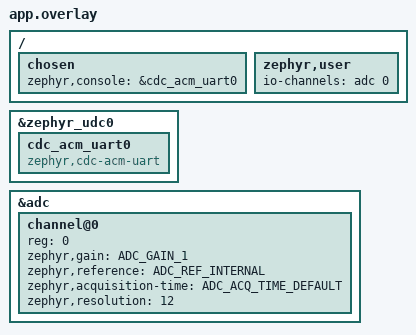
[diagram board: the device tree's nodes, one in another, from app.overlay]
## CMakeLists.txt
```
cmake_minimum_required(VERSION 3.20.0)
find_package(Zephyr REQUIRED HINTS $ENV{ZEPHYR_BASE})
project(temp-sensor)

target_sources(app PRIVATE src/main.c)
```

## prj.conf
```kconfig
CONFIG_SERIAL=y
CONFIG_CONSOLE=y
CONFIG_UART_CONSOLE=y
CONFIG_UART_LINE_CTRL=y

CONFIG_USB_DEVICE_STACK=y
CONFIG_USB_DEVICE_PRODUCT="Zephyr Temp Sensor"
CONFIG_USB_CDC_ACM=y

CONFIG_ADC=y
```

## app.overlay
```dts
#include <zephyr/dt-bindings/adc/adc.h>

/ {
	chosen {
		zephyr,console = &cdc_acm_uart0;
	};

	zephyr,user {
		io-channels = <&adc 0>;
	};
};

&zephyr_udc0 {
	cdc_acm_uart0: cdc_acm_uart0 {
		compatible = "zephyr,cdc-acm-uart";
	};
};

&adc {
	#address-cells = <1>;
	#size-cells = <0>;

	channel@0 {
		reg = <0>;
		zephyr,gain = "ADC_GAIN_1";
		zephyr,reference = "ADC_REF_INTERNAL";
		zephyr,acquisition-time = <ADC_ACQ_TIME_DEFAULT>;
		zephyr,resolution = <12>;
	};
};
```

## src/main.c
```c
#include <zephyr/kernel.h>
#include <zephyr/device.h>
#include <zephyr/drivers/uart.h>
#include <zephyr/drivers/adc.h>
#include <zephyr/usb/usb_device.h>

static const struct adc_dt_spec adc_chan =
	ADC_DT_SPEC_GET(DT_PATH(zephyr_user));

int main(void)
{
	const struct device *const console = DEVICE_DT_GET(DT_CHOSEN(zephyr_console));
	uint32_t dtr = 0;

	if (usb_enable(NULL)) {
		return 0;
	}

	while (!dtr) {
		uart_line_ctrl_get(console, UART_LINE_CTRL_DTR, &dtr);
		k_sleep(K_MSEC(100));
	}

	if (!adc_is_ready_dt(&adc_chan)) {
		printk("ADC not ready\n");
		return 0;
	}

	if (adc_channel_setup_dt(&adc_chan) < 0) {
		printk("ADC channel setup failed\n");
		return 0;
	}

	int16_t sample;
	struct adc_sequence seq = {
		.buffer = &sample,
		.buffer_size = sizeof(sample),
	};
	adc_sequence_init_dt(&adc_chan, &seq);

	printk("Temp sensor app started\n");

	const int N = 256;

	while (1) {
		int32_t raw_sum = 0;
		int good = 0;

		for (int i = 0; i < N; i++) {
			if (adc_read_dt(&adc_chan, &seq) == 0) {
				raw_sum += sample;
				good++;
			}
		}

		if (good == 0) {
			printk("ADC read failed\n");
		} else {
			int32_t raw_avg = raw_sum / good;
			int32_t mv = raw_avg;
			adc_raw_to_millivolts_dt(&adc_chan, &mv);
			/* LMT85 at 3.3V supply: T(°C) = (1822 - V_mV) / 10.88 */
			int32_t temp_c100 = (1822 - mv) * 10000 / 1088;
			printk("raw=%d  V=%d mV  T=%d.%02d C\n",
			       raw_avg, mv,
			       temp_c100 / 100,
			       (temp_c100 < 0 ? -temp_c100 : temp_c100) % 100);
		}

		k_sleep(K_MSEC(500));
	}

	return 0;
}
```
